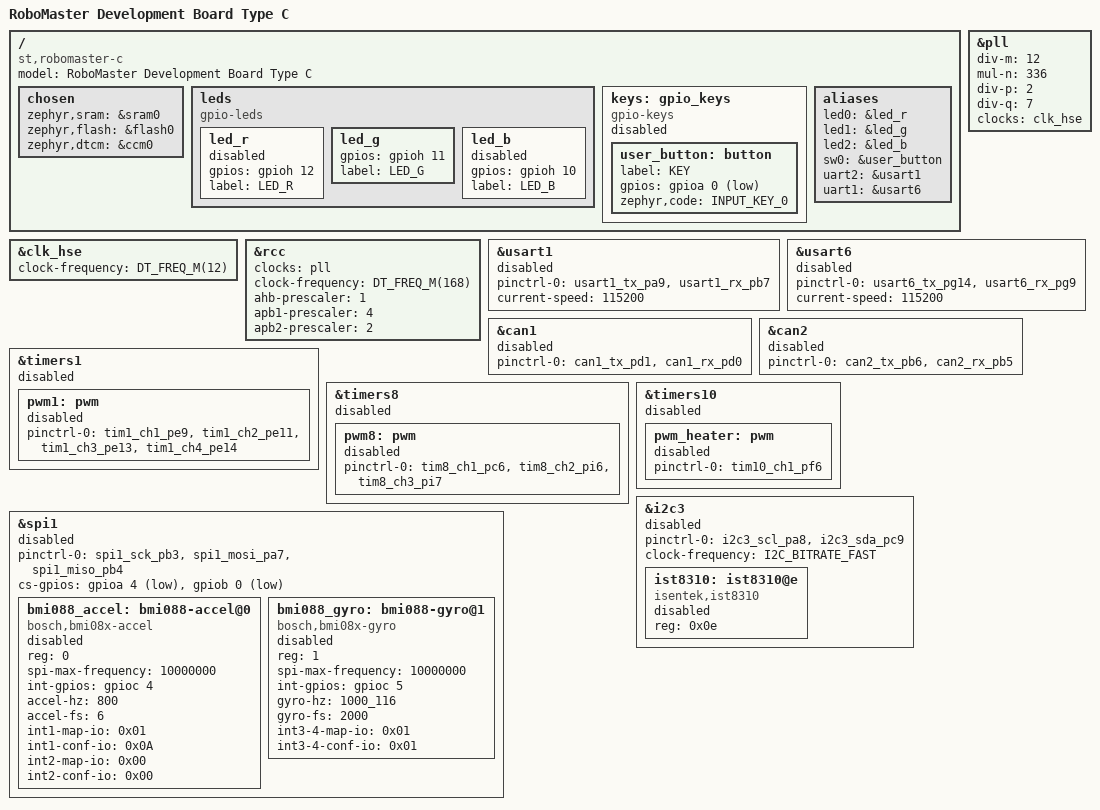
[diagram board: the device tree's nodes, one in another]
/*
 * Copyright (c) 2026 RoboMaster C-Type Zephyr Adaptation
 *
 * SPDX-License-Identifier: Apache-2.0
 */

/dts-v1/;
#include <st/f4/stm32f407Xg.dtsi>
#include <st/f4/stm32f407i(e-g)hx-pinctrl.dtsi>
#include <zephyr/dt-bindings/input/input-event-codes.h>

/ {
	model = "RoboMaster Development Board Type C";
	compatible = "st,robomaster-c";

	chosen {
		/*
		 * 控制台与 shell 均走 SEGGER RTT (CONFIG_RTT_CONSOLE / CONFIG_SHELL_BACKEND_RTT)。
		 * RTT 不是 DT 节点，通过 Kconfig 选择即可，因此 chosen 中不再指向 usart1，
		 * usart1 (丝印 UART2, PA9/PB7) 被释放给应用层自由使用。
		 */
		zephyr,sram = &sram0;
		zephyr,flash = &flash0;
		zephyr,dtcm = &ccm0;
	};

	/* 3 路 RGB LED，共阳极 + N-MOSFET 拉地，高电平点亮 */
	leds: leds {
		compatible = "gpio-leds";

		led_r: led_r {
			gpios = <&gpioh 12 GPIO_ACTIVE_HIGH>;
			label = "LED_R";
			status = "disabled";
		};

		led_g: led_g {
			gpios = <&gpioh 11 GPIO_ACTIVE_HIGH>;
			label = "LED_G";
			status = "okay";
		};

		led_b: led_b {
			gpios = <&gpioh 10 GPIO_ACTIVE_HIGH>;
			label = "LED_B";
			status = "disabled";
		};
	};

	/* 板载用户按键，按下为低 */
	keys: gpio_keys {
		compatible = "gpio-keys";
		status = "disabled";

		user_button: button {
			label = "KEY";
			/* 板载已有外部偏置网络（VCC_BAT 分压 + 1K 下拉），
			 * 不使能 MCU 内部上拉，避免与外部电阻冲突造成电平漂移。
			 */
			gpios = <&gpioa 0 GPIO_ACTIVE_LOW>;
			zephyr,code = <INPUT_KEY_0>;
		};
	};

	aliases {
		led0 = &led_r;
		led1 = &led_g;
		led2 = &led_b;
		sw0 = &user_button;
		uart2 = &usart1;
		uart1 = &usart6;
	};
};

/* ------------------------- 时钟系统 ------------------------- */
/* HSE = 12 MHz 外部晶振, 目标 SYSCLK = 168 MHz
 * PLL: VCO_in = 12/12 = 1 MHz, VCO_out = 1*336 = 336 MHz
 *      SYSCLK = 336/2 = 168 MHz, USB/SDIO = 336/7 ≈ 48 MHz
 */
&clk_hse {
	clock-frequency = <DT_FREQ_M(12)>;
	status = "okay";
};

&pll {
	div-m = <12>;
	mul-n = <336>;
	div-p = <2>;
	div-q = <7>;
	clocks = <&clk_hse>;
	status = "okay";
};

&rcc {
	clocks = <&pll>;
	clock-frequency = <DT_FREQ_M(168)>;
	ahb-prescaler = <1>;
	apb1-prescaler = <4>;
	apb2-prescaler = <2>;
};

/* ------------------------- 串口 ------------------------- */
/* 丝印 UART2 = 芯片 USART1: PA9 TX / PB7 RX, 4-pin 接口
 * 控制台已切换到 SEGGER RTT，此 UART 释放给应用层自由使用；
 * 默认保持 disabled，由工程按需在项目级 overlay 中打开。
 */
&usart1 {
	pinctrl-0 = <&usart1_tx_pa9 &usart1_rx_pb7>;
	pinctrl-names = "default";
	current-speed = <115200>;
	status = "disabled";
};

/* 丝印 UART1 = 芯片 USART6: PG14 TX / PG9 RX, 3-pin 接口（常接裁判系统） */
&usart6 {
	pinctrl-0 = <&usart6_tx_pg14 &usart6_rx_pg9>;
	pinctrl-names = "default";
	current-speed = <115200>;
	status = "disabled";
};

/* ------------------------- CAN 总线 ------------------------- */
/* CAN1: PD1 TX / PD0 RX (2-pin 接口) */
&can1 {
	pinctrl-0 = <&can1_tx_pd1 &can1_rx_pd0>;
	pinctrl-names = "default";
	status = "disabled";
};

/* CAN2: PB6 TX / PB5 RX (4-pin 接口, 带 5V 供电) */
&can2 {
	pinctrl-0 = <&can2_tx_pb6 &can2_rx_pb5>;
	pinctrl-names = "default";
	status = "disabled";
};

/* ------------------------- PWM 输出 ------------------------- */
/* PWM1~4: TIM1_CH1~4 => PE9 / PE11 / PE13 / PE14 */
&timers1 {
	status = "disabled";

	pwm1: pwm {
		status = "disabled";
		pinctrl-0 = <&tim1_ch1_pe9 &tim1_ch2_pe11
			     &tim1_ch3_pe13 &tim1_ch4_pe14>;
		pinctrl-names = "default";
	};
};

/* PWM5~7: TIM8_CH1~3 => PC6 / PI6 / PI7 */
&timers8 {
	status = "disabled";

	pwm8: pwm {
		status = "disabled";
		pinctrl-0 = <&tim8_ch1_pc6 &tim8_ch2_pi6 &tim8_ch3_pi7>;
		pinctrl-names = "default";
	};
};

/* IMU 恒温加热: TIM10_CH1 => PF6 (高电平满功率 0.58W) */
&timers10 {
	status = "disabled";

	pwm_heater: pwm {
		status = "disabled";
		pinctrl-0 = <&tim10_ch1_pf6>;
		pinctrl-names = "default";
	};
};

/* ------------------------- 板载传感器 ------------------------- */
/* SPI1: SCK=PB3, MOSI=PA7, MISO=PB4 (BMI088 6-axis IMU)
 *   CS1_Accel (BMI088 accel)  = PA4, active low
 *   CS1_Gyro  (BMI088 gyro)   = PB0, active low
 *   INT1_Accel                = PC4 (data ready / motion)
 *   INT1_Gyro                 = PC5 (data ready)
 *   BMI088 datasheet allows up to 10 MHz SPI clock.
 *
 *   使用 Zephyr 上游 "bosch,bmi08x-accel" / "bosch,bmi08x-gyro" 驱动 (drivers/sensor/bosch/bmi08x)。
 *   accel-hz/accel-fs/gyro-hz/gyro-fs 为 binding required property，这里给出默认值，
 *   项目级 overlay 可按需 override。
 */
&spi1 {
	pinctrl-0 = <&spi1_sck_pb3 &spi1_mosi_pa7 &spi1_miso_pb4>;
	pinctrl-names = "default";
	cs-gpios = <&gpioa 4 GPIO_ACTIVE_LOW>,
		   <&gpiob 0 GPIO_ACTIVE_LOW>;
	status = "disabled";

	bmi088_accel: bmi088-accel@0 {
		compatible = "bosch,bmi08x-accel";
		reg = <0>;
		spi-max-frequency = <10000000>;
		int-gpios = <&gpioc 4 GPIO_ACTIVE_HIGH>;
		accel-hz = "800";
		accel-fs = <6>;
		/* INT1: DRDY 映射；push-pull + active-high + output-enable */
		int1-map-io = <0x01>;
		int1-conf-io = <0x0A>;
		/* INT2 未引出；置 0 以满足 driver 对属性的强制存在要求 */
		int2-map-io = <0x00>;
		int2-conf-io = <0x00>;
		status = "disabled";
	};

	bmi088_gyro: bmi088-gyro@1 {
		compatible = "bosch,bmi08x-gyro";
		reg = <1>;
		spi-max-frequency = <10000000>;
		int-gpios = <&gpioc 5 GPIO_ACTIVE_HIGH>;
		gyro-hz = "1000_116";
		gyro-fs = <2000>;
		/* INT3 数据就绪中断, push-pull, active-high */
		int3-4-map-io = <0x01>;
		int3-4-conf-io = <0x01>;
		status = "disabled";
	};
};

/* I2C3: SCL=PA8, SDA=PC9 (IST8310 磁力计)
 *   Fast-mode 400kHz; 默认 I2C 地址 0x0E (CAD0/CAD1 硬连接)。
 *   使用 Zephyr 上游 "isentek,ist8310" 驱动 (drivers/sensor/ist8310)，
 *   其不管理 RSTN/DRDY 引脚；应用层通过 zephyr,user 暴露的 GPIO 自行完成复位序列。
 */
&i2c3 {
	pinctrl-0 = <&i2c3_scl_pa8 &i2c3_sda_pc9>;
	pinctrl-names = "default";
	clock-frequency = <I2C_BITRATE_FAST>;
	status = "disabled";

	ist8310: ist8310@e {
		compatible = "isentek,ist8310";
		reg = <0x0e>;
		status = "disabled";
	};
};
